# STM32U585 register map
File version: 1.4
CPU: CM33 r0p1, little endian, MPU, FPU, 4 interrupt priority bits
Registers are 32-bit, read-write, reset 0x0 unless marked. A register's access mark holds for its fields unless they carry their own. Offsets are from the block's base; [hi:lo] are bit positions; {n}, {i} and the like mark numbered series.

## AES — Advanced encryption standard hardware accelerator
Base 0x420C0000
Same registers: SEC_AES 0x520C0000
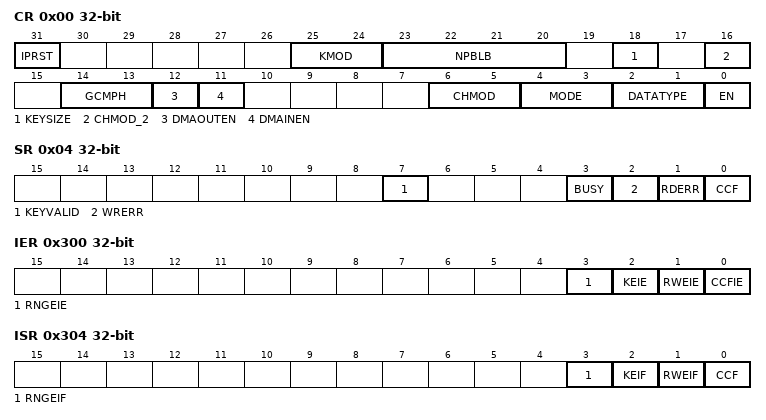
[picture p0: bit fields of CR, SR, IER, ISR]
0x00 CR — control register
  [31] IPRST
  [25:24] KMOD
    0=Normal key mode. Key registers are freely usable; 2=Shared key mode. If shared key mode is properly initialized in SAES peripheral, the AES peripheral automatically loads its key registers with the data stored in the SAES key registers. The key value is available in AES key registers when BUSY bit is cleared and KEYVALID is set in the AES_SR register. Key error flag KEIF is set otherwise in the AES_ISR register
  [23:20] NPBLB
  [18] KEYSIZE
    0=AES128 (128); 1=AES256 (256)
  [16] CHMOD_2
    0=CHMOD (Mode as per CHMOD (ECB, CBC, CTR, GCM)); 1=CCM (Counter with CBC-MAC (CCM) - CHMOD must be 0 (ECB))
  [14:13] GCMPH
    0=Init phase; 1=Header phase; 2=Payload phase; 3=Final Phase
  [12] DMAOUTEN — Enable DMA management of data output phase
    0=Disable DMA Output; 1=Enabled DMA Output
  [11] DMAINEN — Enable DMA management of data input phase
    0=Disable DMA Input; 1=Enable DMA Input
  [6:5] CHMOD — AES chaining mode
    0=ECB (Electronic codebook (ECB) / Counter with CBC-MAC (CCM) if CHMOD2 is 1); 1=CBC (Cipher-block chaining (CBC)); 2=CTR (Counter mode (CTR)); 3=GCM (Galois counter mode (GCM) and Galois message authentication code (GMAC))
  [4:3] MODE — AES operating mode
    0=Mode 1: encryption; 1=Mode 2: key derivation (or key preparation for ECB/CBC decryption); 2=Mode 3: decryption; 3=Mode 4: key derivation then single decryption
  [2:1] DATATYPE — Data type selection (for data in and data out to/from the cryptographic block)
    0=None (Word); 1=Half-word (16-bit); 2=Byte (8-bit); 3=Bit
  [0] EN — AES enable
    0=Disabled (Disable AES); 1=Enabled (Enable AES)
0x04 SR ro — status register
  [7] KEYVALID — Key Valid flag
  [3] BUSY
    0=Idle; 1=Busy
  [2] WRERR — Write error flag
    0=NoError (Write error not detected); 1=Error (Write error detected)
  [1] RDERR — Read error flag
    0=NoError (Read error not detected); 1=Error (Read error detected)
  [0] CCF — Computation complete flag
    0=Complete (Computation complete); 1=NotComplete (Computation not complete)
0x08 DINR wo — data input register
  [31:0] DIN — Input data word
0x0C DOUTR ro — data output register
  [31:0] DOUT — Output data word
0x10 KEYR0 wo — key register 0
  [31:0] KEY — Cryptographic key, bits [31:0]
0x14 KEYR1 wo — key register 1
  [31:0] KEY — Cryptographic key, bits [63:32]
0x18 KEYR2 wo — key register 2
  [31:0] KEYR — Cryptographic key, bits [95:64]
0x1C KEYR3 wo — key register 3
  [31:0] AES_KEYR3 — Cryptographic key, bits [127:96]
{0x20+4i} IVR{i} (i=0..3) — initialization vector register {i}
  [31:0] IVI — Initialization vector input, bits [{32i+31}:{32i}]
{0x20+4i} KEYR{i} wo (i=4..7) — key register {i}
  [31:0] KEY — Cryptographic key, bits [{32i+31}:{32i}]
{0x40+4i} SUSP{i}R wo (i=0..7) — suspend registers
  [31:0] SUSP — AES suspend
0x300 IER — interrupt enable register
  [all] fields
    0=Disabled (Interrupt is disabled (masked)); 1=Enabled (Interrupt is enabled (not masked))
  [3] RNGEIE — Key error interrupt flag
  [2] KEIE — Key error interrupt flag
  [1] RWEIE — Read or write error interrupt flag
  [0] CCFIE — Computation complete flag
0x304 ISR ro — interrupt status register
  [3] RNGEIF — Key error interrupt flag
    0=No error detected; 1=Error (The error detected)
  [2] KEIF — Key error interrupt flag
    0=No error detected; 1=Error (The error detected)
  [1] RWEIF — Read or write error interrupt flag
    0=No error detected; 1=Error (The error detected)
  [0] CCF — Computation complete flag
    0=NotCompleted (Computation not completed); 1=Completed (Computation completed)
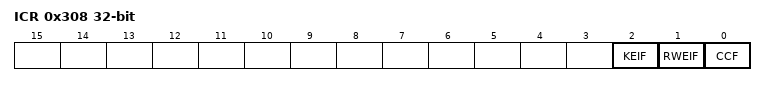
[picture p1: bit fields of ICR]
0x308 ICR wo — interrupt clear register
  [all] fields
    1=Clear (Setting this bit clears corresponding interrupt status bit)
  [2] KEIF — Key error interrupt flag clear
  [1] RWEIF — Read or write error interrupt flag clear
  [0] CCF — Computation complete flag clear

## SAES — Secure AES coprocessor
Base 0x420C0C00
Same registers: SEC_SAES 0x520C0C00
Registers as AES (with AES read as SAES), without SUSP{n}R (n=0..7); these are added or differ:
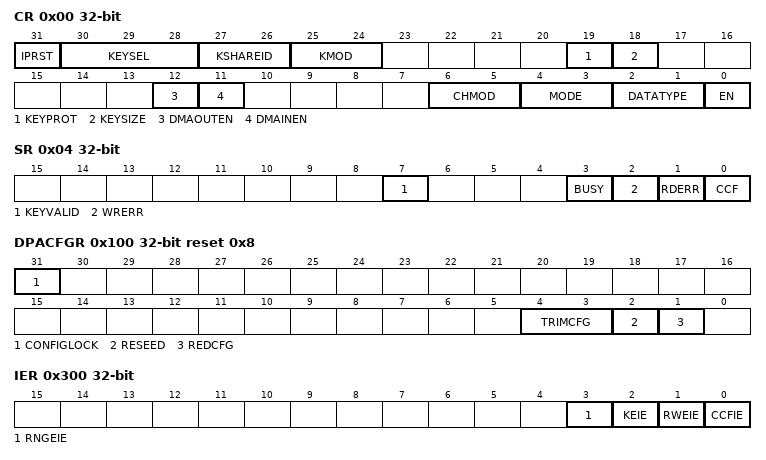
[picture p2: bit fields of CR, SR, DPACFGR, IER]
0x00 CR — control register
  [31] IPRST
  [30:28] KEYSEL
  [27:26] KSHAREID
  [25:24] KMOD
  [19] KEYPROT
  [18] KEYSIZE
  [12] DMAOUTEN
  [11] DMAINEN
  [6:5] CHMOD
  [4:3] MODE
  [2:1] DATATYPE
  [0] EN — SAES enable
0x04 SR ro — status register
  [7] KEYVALID — Key Valid flag
  [3] BUSY
  [2] WRERR — Write error flag
  [1] RDERR — Read error flag
  [0] CCF — Computation complete flag
0x100 DPACFGR access per field reset 0x8 — configuration register
  [31] CONFIGLOCK ro, [4:3] TRIMCFG rw, [2] RESEED rw, [1] REDCFG rw
0x300 IER — interrupt enable register
  [3] RNGEIE
  [2] KEIE — Key error interrupt enable
  [1] RWEIE — Read or write error interrupt enable
  [0] CCFIE — Computation complete flag interrupt enable
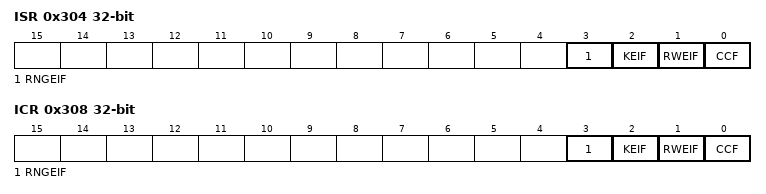
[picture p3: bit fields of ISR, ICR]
0x304 ISR ro — interrupt status register
  [3] RNGEIF
  [2] KEIF — Key error interrupt flag
  [1] RWEIF — Read or write error interrupt flag
  [0] CCF — Computation complete flag
0x308 ICR wo — interrupt clear register
  [3] RNGEIF
  [2] KEIF — Key error interrupt flag clear
  [1] RWEIF — Read or write error interrupt flag clear
  [0] CCF — Computation complete flag clear
